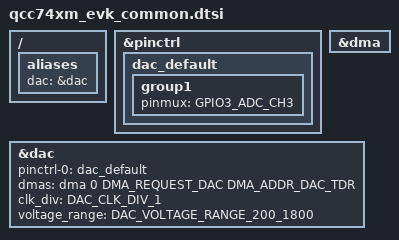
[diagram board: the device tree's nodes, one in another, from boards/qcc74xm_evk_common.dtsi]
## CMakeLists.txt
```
# Copyright (c) 2026 Qualcomm Technologies, Inc. and/or its subsidiaries
# SPDX-License-Identifier: Apache-2.0

cmake_minimum_required(VERSION 3.20.0)

find_package(Zephyr REQUIRED HINTS $ENV{ZEPHYR_BASE})
project(dac_dma_api)

FILE(GLOB app_sources src/*.c)
target_sources(app PRIVATE ${app_sources})
```

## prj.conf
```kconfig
CONFIG_ZTEST=y

CONFIG_DAC=y
# CONFIG_TEST_USERSPACE is disabled: requires 'gperf' tool at build time
# (gperf generates the kobject hash for Zephyr userspace syscall tables).
# This is a build_only test that validates DAC DMA, not userspace isolation;
# re-enable when gperf is available in the build environment.
# CONFIG_TEST_USERSPACE=y
```

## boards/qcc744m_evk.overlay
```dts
/*
 * Copyright (c) 2026 Qualcomm Technologies, Inc. and/or its subsidiaries.
 *
 * SPDX-License-Identifier: BSD-3-Clause
 */

#include "qcc74xm_evk_common.dtsi"
```

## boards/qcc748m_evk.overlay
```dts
/*
 * Copyright (c) 2025 Qualcomm Technologies, Inc. and/or its subsidiaries.
 *
 * SPDX-License-Identifier: Apache-2.0
 */

#include "qcc74xm_evk_common.dtsi"
```

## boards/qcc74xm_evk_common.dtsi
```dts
/*
 * Copyright (c) 2026 Qualcomm Technologies, Inc. and/or its subsidiaries
 * SPDX-License-Identifier: BSD-3-Clause
 */

/ {
	aliases {
		dac = &dac;
	};
};

&pinctrl {
	dac_default: dac_default {
		group1 {
			pinmux = <GPIO3_ADC_CH3>;
		};
	};
};

&dma {
	status = "okay";
};

&dac {
	status = "okay";
	pinctrl-0 = <&dac_default>;
	pinctrl-names = "default";
	dmas = <&dma 0  DMA_REQUEST_DAC  DMA_ADDR_DAC_TDR>;
	clk_div = <DAC_CLK_DIV_1>;
	voltage_range = <DAC_VOLTAGE_RANGE_200_1800>;
};
```

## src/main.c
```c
/*
 * Copyright (c) 2020 Libre Solar Technologies GmbH
 * SPDX-License-Identifier: Apache-2.0.
 *
 * Copyright (c) 2026 Qualcomm Technologies, Inc. and/or its subsidiaries
 * SPDX-License-Identifier: BSD-3-Clause
 * Not a contribution.
 */


#include <zephyr/drivers/dac.h>
#include <zephyr/drivers/dac/dac_qcc74x.h>
#include <zephyr/drivers/dma.h>
#include <zephyr/kernel.h>
#include <zephyr/ztest.h>

#if defined(CONFIG_BOARD_QCC743M_EVK) ||  \
	defined(CONFIG_BOARD_QCC744M_EVK) || \
	defined(CONFIG_BOARD_QCC748M_EVK)

#define DAC_DEVICE_NODE	        DT_NODELABEL(dac)
#define DAC_RESOLUTION          12
#define DAC_CHANNEL_ID          0

#else
#error "Unsupported board."
#endif

static __aligned(32) uint32_t SIN_LIST[] = {
	500, 506, 513, 519, 525, 531, 538, 544, 550, 556,
	563, 569, 575, 581, 587, 594, 600, 606, 612, 618,
	624, 630, 636, 642, 648, 654, 660, 666, 672, 678,
	684, 690, 696, 701, 707, 713, 718, 724, 730, 735,
	741, 746, 752, 757, 762, 768, 773, 778, 784, 789,
	794, 799, 804, 809, 814, 819, 823, 828, 833, 838,
	842, 847, 851, 856, 860, 864, 869, 873, 877, 881,
	885, 889, 893, 897, 901, 904, 908, 912, 915, 919,
	922, 925, 929, 932, 935, 938, 941, 944, 947, 950,
	952, 955, 958, 960, 962, 965, 967, 969, 971, 973,
	975, 977, 979, 981, 983, 984, 986, 987, 989, 990,
	991, 992, 993, 994, 995, 996, 997, 997, 998, 999,
	999, 999, 1000, 1000, 1000, 1000, 1000, 1000, 1000,
	999, 999, 999, 998, 998, 997, 996, 995, 994, 993,
	992, 991, 990, 989, 987, 986, 984, 983, 981, 979,
	978, 976, 974, 972, 970, 967, 965, 963, 960, 958, 955, 953, 950, 947, 944, 941, 938, 935,
	932, 929, 926, 922, 919, 916, 912, 908, 905, 901, 897, 893, 890, 886, 882, 878, 873, 869,
	865, 861, 856, 852, 847, 843, 838, 833, 829, 824, 819, 814, 809, 804, 799, 794, 789, 784,
	779, 774, 768, 763, 758, 752, 747, 741, 736, 730, 725, 719, 714, 708, 702, 696, 691, 685, 679,
	673, 667, 661, 655, 649, 643, 637, 631, 625, 619, 613, 607, 601, 594, 588, 582, 576, 570, 563,
	557, 551, 545, 538, 532, 526, 520, 513, 507, 501, 495, 488, 482, 476, 469, 463, 457, 451, 444,
	438, 432, 426, 420, 413, 407, 401, 395, 389, 383, 376, 370, 364, 358, 352, 346, 340, 334, 329,
	323, 317, 311, 305, 299, 294, 288, 282, 277, 271, 265, 260, 254, 249, 244, 238, 233, 228, 222,
	217, 212, 207, 202, 197, 192, 187, 182, 177, 172, 168, 163, 158, 154, 149, 145, 141, 136, 132, 128, 124,
	119, 115, 111, 107, 104, 100, 96, 92, 89, 85, 82, 78, 75, 72, 69, 65, 62, 59, 56, 54, 51, 48, 45, 43, 40, 38,
	36, 33, 31, 29, 27, 25, 23, 21, 19, 18, 16, 14, 13, 12, 10, 9, 8, 7, 6, 5, 4, 3, 3, 2, 2, 1, 1, 0, 0, 0, 0, 0, 0, 0, 1, 1, 1, 2, 2, 3, 4, 5, 5, 6, 8, 9, 10, 11,
	12, 14, 15, 17, 19, 20, 22, 24, 26, 28, 30, 32, 35, 37, 39, 42, 44, 47, 50, 52, 55, 58, 61, 64, 67, 71, 74, 77, 81, 84, 87, 91, 95, 98, 102, 106, 110, 114, 118, 122,
	126, 130, 135, 139, 143, 148, 152, 157, 161, 166, 171, 175, 180, 185, 190, 195, 200, 205, 210, 215, 220, 226, 231, 236, 242, 247, 252, 258, 263, 269, 274, 280, 286,
	291, 297, 303, 309, 315, 320, 326, 332, 338, 344, 350, 356, 362, 368, 374, 380, 386, 392, 399, 405, 411, 417, 423, 430, 436, 442, 448, 455, 3024, 3024, 3024, 3024, 3024, 3024
    };

static const struct dac_channel_cfg dac_ch_cfg = {
	.channel_id  = DAC_CHANNEL_ID,
	.resolution  = DAC_RESOLUTION,
	.buffered = true
};

const struct device *get_dac_device(void)
{
	return DEVICE_DT_GET(DAC_DEVICE_NODE);
}

static const struct device *init_dac(void)
{
	int ret;
	const struct device *const dac_dev = DEVICE_DT_GET(DAC_DEVICE_NODE);

	zassert_true(device_is_ready(dac_dev), "DAC device is not ready");

	ret = dac_channel_setup(dac_dev, &dac_ch_cfg);
	zassert_ok(ret, "Setting up of the first channel failed with code %d", ret);

	return dac_dev;
}

/*
 * test_dac_write_dma
 */
ZTEST(dac, test_task_write_dma)
{
	int ret;

	const struct device *dac = init_dac();
	ret = dac_write_dma(dac,sizeof(SIN_LIST), (void*)SIN_LIST);

	zassert_ok(ret, "dac_write_value() failed with code %d", ret);
}

static void *dac_setup(void)
{
	k_object_access_grant(get_dac_device(), k_current_get());

	return NULL;
}

ZTEST_SUITE(dac, NULL, dac_setup, NULL, NULL, NULL);
```
